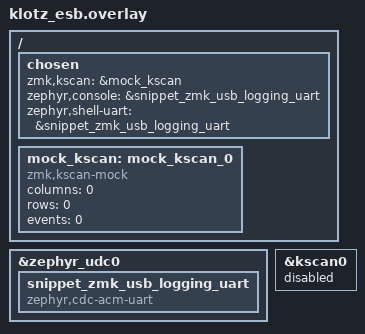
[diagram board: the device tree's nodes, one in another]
#include "../klotz/klotz.dtsi"
#include "klotz_esb_addr.dtsi"

/ {
    chosen {
        zmk,kscan = &mock_kscan;
        zephyr,console = &snippet_zmk_usb_logging_uart;
        zephyr,shell-uart = &snippet_zmk_usb_logging_uart;
    };

    mock_kscan: mock_kscan_0 {
        compatible = "zmk,kscan-mock";
        columns = <0>;
        rows = <0>;
        events = <0>;
    };
};

&zephyr_udc0 {
    snippet_zmk_usb_logging_uart: snippet_zmk_usb_logging_uart {
        compatible = "zephyr,cdc-acm-uart";
    };
};

&kscan0 {
    status = "disabled";
};
